# HR_C7000_DM32 register map
Vendor: Dahua Technology (chip); Baofeng (radio product); Series: HR_C7000; File version: 0.1-dm32re-draft
CPU: other r0p0, little endian, no MPU, no FPU, 0 interrupt priority bits
Registers are 32-bit, read-write, reset 0x0 unless marked. A register's access mark holds for its fields unless they carry their own. Offsets are from the block's base; [hi:lo] are bit positions.

## SDIO — SD/SDIO host, Synopsys DesignWare Mobile Storage (DS §5.5, p.285-325; FIFO depth 128, data FIFO window from +0x200). FW: no access found; QEMU: reports no card, as on the radio.
Base 0x15000000
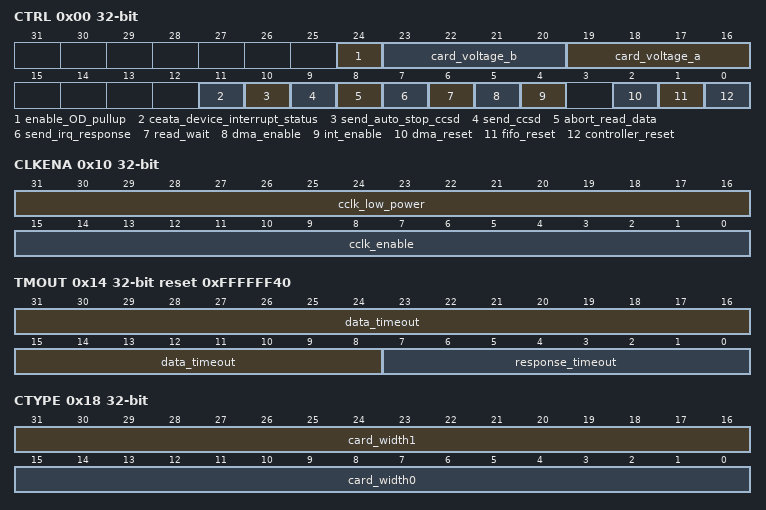
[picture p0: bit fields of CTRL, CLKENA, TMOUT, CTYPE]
0x00 CTRL — Control registers. DS §5.5.5.1 p.305. Note: H/S Represents hardware reset and software reset Reset 0x0 (DS).
  [24] enable_OD_pullup — External open-drain pull-up. 0: disabled; 1: enabled [reset 0x0] [access RW]
  [23:20] card_voltage_b — Card regulator B voltage setting, output to card_volt_b (optional; usable as a general output port) [reset 0x0] [access RW]
  [19:16] card_voltage_a — Card regulator A voltage setting, output to card_volt_a. Printed card_voltage_b (duplicate of [23:20]); DW_mobile_storage names this card_voltage_a [reset 0x0] [access RW]
  [11] ceata_device_interrupt_status — 0: CE-ATA device interrupts disabled; 1: enabled [reset 0x0] [access RW]
  [10] send_auto_stop_ccsd — Send internally generated STOP after sending CCSD to a CE-ATA device; send_ccsd must also be set [reset 0x0] [access RW]
  [9] send_ccsd — Send command-completion-signal-disable to a CE-ATA device [reset 0x0] [access RW]
  [8] abort_read_data — 1: reset the data state machine to IDLE; self-clearing [reset 0x0] [access RW]
  [7] send_irq_response — 1: send automatic IRQ response [reset 0x0] [access RW]
  [6] read_wait — 0: clear read wait; 1: assert read wait [reset 0x0] [access RW]
  [5] dma_enable — DMA transfer mode enable [reset 0x0] [access RW]
  [4] int_enable — Global interrupt enable [reset 0x0] [access RW]
  [2] dma_reset — Reset internal DMA interface logic; self-clears after two AHB clocks [reset 0x0] [access RW]
  [1] fifo_reset — Reset FIFO; self-clears when done [reset 0x0] [access RW]
  [0] controller_reset — Reset controller; self-clears after two AHB and two cclk_in cycles [reset 0x0] [access RW]
0x04 PWREN — Power-on enable register. DS §5.5.5.2 p.307. Reset 0x0 (DS).
  [0] power_enable — Card power: 1 = powered on, 0 = powered off. One bit per card; this design uses one controller per SD card and only bit 0 [reset 0x0] [access RW]
0x08 CLKDIV — Clock divider register. DS §5.5.5.3 p.307. Reset 0x0 (DS).
  [7:0] clk_divider0 — Divider 0: cclk_out = cclk_in / (2 * value); 0 = no division, 255 = divide by 510. Bits [31:8] (clk_divider1/2/3) not used, write 0 [reset 0x0] [access RW]
0x0C CLKSRC ro — Clock source register. DS §5.5.5.4 p.307. Reset 0x0 (DS).
  [31:0] clk_source — Select each SD The driving clock of the memory has the following relationship 00b : Select Clock divider_0 , 01 : Select Clock divider_1 , 10b : Select Clock divider_2 , 11 : Select Clock divider_3 , each controller in the project only contains clk_divder0 , which is fixed to 0 [reset 0x0] [access RO]
0x10 CLKENA — Clock enable register. DS §5.5.5.5 p.309. Reset 0x0 (DS).
  [31:16] cclk_low_power — 16 S D memory or 1 Zhang MMC Memory low power control 0 : Non-low power mode; 1 : Low power mode , the project only configures bit[16] , and all other bits are fixed to 0 [reset 0x0] [access RW]
  [15:0] cclk_enable — 16 S D memory or 1 Zhang MMC Memory clock enable control , 0 : Clock is invalid; 1 : Clock is enabled The project only configures bit[0] , and all other bits are fixed to 0 [reset 0x0] [access RW]
0x14 TMOUT reset 0xFFFFFF40 — Timeout register. DS §5.5.5.6 p.309. Reset 0xffffff40 (DS).
  [31:8] data_timeout — The memory card data reading timeout value is set, and the memory card clock starts counting after it ends. cclk_out of the selected card The period value is the unit time [reset 0xffffff] [access RW]
  [7:0] response_timeout — Reply timeout setting, with cclk_out The period value is the unit time [reset 0x40] [access RW]
0x18 CTYPE — Card Type Register. DS §5.5.5.7 p.309. Reset 0x0 (DS).
  [31:16] card_width1 — Indicates whether each memory card is 8-bit type 0 : non- 8-bit Type; 1 : 8-bit If there is no 8-bit application in the type project , write all 0s in this segment. [reset 0x0] [access RW]
  [15:0] card_width0 — Indicates whether each memory card is 1-bit or 4-bit type 0 : 1-bit Type ; 1 : 4-bit type The project only configures bit[0] and all other bits are written to 0 [reset 0x0] [access RW]
0x1C BLKSIZ reset 0x200 — Block size register. DS §5.5.5.8 p.310. Reset 0x200 (DS).
  [15:0] block_size — Block size (bytes ) [reset 0x200] [access RW]
0x20 BYTCNT reset 0x200 — Byte Count Register. DS §5.5.5.9 p.310. Reset 0x200 (DS).
  [31:0] byte_count — The number of bytes of data to be transferred For unknown data size transmission, 0 must be written [reset 0x200] [access RW]
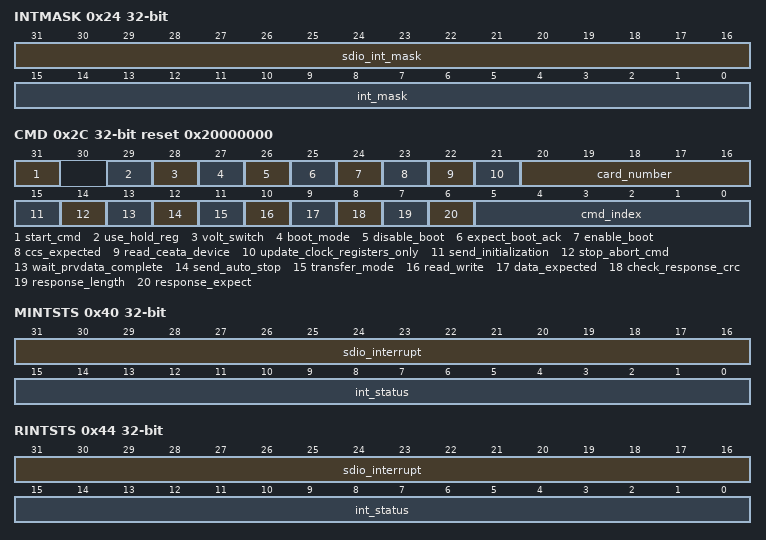
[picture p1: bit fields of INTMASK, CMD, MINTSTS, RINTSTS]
0x24 INTMASK — Interrupt Mask Register. DS §5.5.5.10 p.311. Reset 0x0 (DS).
  [31:16] sdio_int_mask — Shield 16 SDIO memory card Interrupt, 0 : mask; 1 : enable The project only configures bit[16] , and all other bits are written to 0 [reset 0x0] [access RW]
  [15:0] int_mask — Shield unwanted interrupts, 0 : Shield; 1 : Enable bit15 : End-bit error(read)/Write no CRC(EBE) bit14: Auto Command Done(ACD) bit13: Start Bit Error(SBE)/Busy Complete Iterrupt(BCI) bit12: Hardware Locked write Error(HLE) bit11: FIFO underrun/overrun Error(FRUN) bit10: Data starvation-by-host timeout(HTO)/Volt_switch_int bit9: Data Read Timeout(DRTO) bit8: Response Timeout(RTO) bit7: Data CRC Error(DCRC) bit6: Responese CRC Error (RCRC) bit5: Receive FIFO Data Request(RXDR) bit4: Transmit FIFO Data Request(TXDR) bit3: Data Transfer Over(DTO) bit2: Command done(CD) bit1: Response Error(RE) bit0: Card Detect(CD) [reset 0x0] [access RW]
0x28 CMDARG — Instruction content segment register. DS §5.5.5.11 p.311. Reset 0x0 (DS).
  [31:0] cmd_arg — 32bit transmitted to the card Instruction content [reset 0x0] [access RW]
0x2C CMD reset 0x20000000 — Command register. DS §5.5.5.12 p.311. Reset 0x20000000 (DS).
  [31] start_cmd — Send instructions, CIU After receiving the instruction, this bit is automatically cleared [reset 0x0] [access RW]
  [29] use_hold_reg — 0 : CMD and DATA Not through HOLD Registers sent to memory card 1 : CMD and DATA through HOLD Register sent to memory card [reset 0x1] [access RW]
  [28] volt_switch — 0 : No voltage switching 1 : Voltage switching enabled, send CMD11 Must be set when [reset 0x0] [access RW]
  [27] boot_mode — Boot Mode selection: 0 : Must boot operate 1 : Optional boot operate [reset 0x0] [access RW]
  [26] disable_boot — Boot invalid [reset 0x0] [access RW]
  [25] expect_boot_ack — ( CIU ) hopes to obtain boot Response [reset 0x0] [access RW]
  [24] enable_boot — Enable boot [reset 0x0] [access RW]
  [23] ccs_expected — 0 : CE_ATA The interrupt in the device is invalid, or the command does not need to get the device CCS (Command Complete Signal .) 1 : CE_ATA Device internal interrupt enable, RW_BLK Need from CE_ATA The device's CCS (Command Completion Signal .) If there is no CE-ATA application, this bit is written as 0. [reset 0x0] [access RW]
  [22] read_ceata_device — 0 : The host does not send data to CE_ATA. Device reads data 1 : Master end to CE-ATA If the device reads data without CE- ATA application, this bit is written as 0. [reset 0x0] [access RW]
  [21] update_clock_registers_only — 0 : Normal instruction sequence 1 : Do not send instructions, only update the clock register [reset 0x0] [access RW]
  [20:16] card_number — Current valid card number [reset 0x0] [access RW]
  [15] send_initialization — 0 : Do not send the initialization sequence before sending the command 1 : Send initialization sequence before sending command 80 must be executed before sending any command to the card. c l o c k s Initialize the card. [reset 0x0] [access RW]
  [14] stop_abort_cmd — 0 : Do not stop or abandon the current data transfer 1 : Stop or abandon the current data transmission [reset 0x0] [access RW]
  [13] wait_prvdata_complete — 0 : Send new command regardless of whether the previous data transmission is completed 1 : Wait for the last data transmission to complete before sending a new command [reset 0x0] [access RW]
  [12] send_auto_stop — 0 : After data transmission is completed, no (automatic) stop command is issued 1 : After data transmission is completed, a (automatic) stop command is issued [reset 0x0] [access RW]
  [11] transfer_mode — 0 : Data block transmission instruction; 1 : Data stream transmission instruction [reset 0x0] [access RW]
  [10] read_write — 0 : read; 1 : write [reset 0x0] [access RW]
  [9] data_expected — 0 : No data reading or writing; 1 : Data reading or writing [reset 0x0] [access RW]
  [8] check_response_crc — 0 : No CRC response Check; 1 : Perform reply CRC check [reset 0x0] [access RW]
  [7] response_length — 0 : short reply; 1 : long reply [reset 0x0] [access RW]
  [6] response_expect — 0 : No reply; 1 : Reply [reset 0x0] [access RW]
  [5:0] cmd_index — Instruction number [reset 0x0] [access RW]
0x30 RESP0 ro — Response reply register 0. DS §5.5.5.13 p.314. Reset 0x0 (DS).
  [31:0] response0 — Reply register 0 , short response or long response bit [31:0] [reset 0x0] [access RO]
0x34 RESP1 ro — Response reply register 1. DS §5.5.5.14 p.315. Reset 0x0 (DS).
  [31:0] response1 — Reply register 1 , long response bits [63:32] auto_Stop response is stored in this register [reset 0x0] [access RO]
0x38 RESP2 ro — Response reply register 2. DS §5.5.5.15 p.315. Reset 0x0 (DS).
  [31:0] response2 — Reply register 2 , long response bit [95:64] [reset 0x0] [access RO]
0x3C RESP3 ro — Response reply register 3. DS §5.5.5.16 p.315. Reset 0x0 (DS).
  [31:0] response3 — Reply register 3 , long response bit [127:96] [reset 0x0] [access RO]
0x40 MINTSTS ro — Interrupt Mask Register. DS §5.5.5.17 p.315. Note: MISTATUS = RINTSTS and INTMASK Reset 0x0 (DS).
  [31:16] sdio_interrupt — Unshielded memory card SDIO Interrupt status, each bit For a card: Bit[31] corresponds to card[15], bit[16] c o r r e s p o nd s t o card[0] . 0 : No SDIO interrupt is sent from the memory card 1 : With SDIO Interrupt sent from memory card The project only uses bit[16] [reset 0x0] [access RO]
  [15:0] int_status — Masked interrupt status (MINTSTS = RINTSTS & INTMASK); same bit assignment as RINTSTS.int_status [reset 0x0] [access RO]
0x44 RINTSTS — Interrupt Status Register. DS §5.5.5.18 p.317. Reset 0x0 (DS).
  [31:16] sdio_interrupt write-1-clears — SDIO interrupt per card, regardless of mask: bit 16 = card 0 ... bit 31 = card 15. Only bit 16 is used in this design. Write 1 to clear [reset 0x0] [access RO/WC]
  [15:0] int_status write-1-clears — Raw interrupt status, write 1 to clear: 15 EBE end-bit error/write no CRC; 14 ACD auto command done; 13 SBE start-bit error/BCI busy complete; 12 HLE hardware locked write error; 11 FRUN FIFO under/overrun; 10 HTO data starvation timeout/volt_switch_int; 9 DRTO data read timeout; 8 RTO response timeout; 7 DCRC data CRC error; 6 RCRC response CRC error; 5 RXDR RX FIFO data request; 4 TXDR TX FIFO data request; 3 DTO data transfer over; 2 CD command done; 1 RE response error; 0 CD card detect [reset 0x0] [access RO/WC]
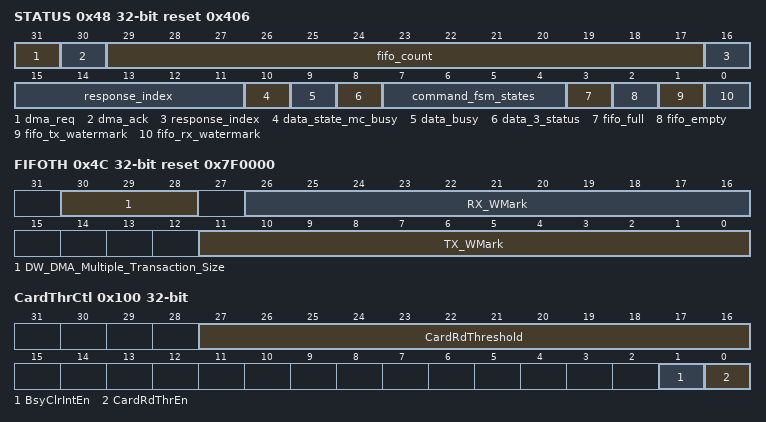
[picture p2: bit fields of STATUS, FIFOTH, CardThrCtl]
0x48 STATUS ro reset 0x406 — Status register, mainly used to check the. DS §5.5.5.19 p.318. Reset 0x406 (DS).
  [31] dma_req — DMA Request signal status bit [reset 0x0] [access RO]
  [30] dma_ack — DMA Response signal status bit [reset 0x0] [access RO]
  [29:17] fifo_count — The amount of data written into the FIFO [reset 0x0] [access RO]
  [16:11] response_index — Previous reply index number [reset 0x0] [access RO]
  [10] data_state_mc_busy — Data sending or receiving state machine is busy [reset 0x1] [access RO]
  [9] data_busy — The opposite value of card_data [0] 0 : Memory card data is not busy; 1 : Memory card data is busy [reset 0x0] [access RO]
  [8] data_3_status — Select the storage card card_datap[3] signal to detect whether there is a card. 0 : Memory card present; 1 : No memory card present [reset 0x0] [access RO]
  [7:4] command_fsm_states — Indicates the current state of the command state machine: 0- IDLE 1- Send init sequence 2- Tx cmd start bit 3- Tx cmd bit 4- Tx cmd index + arg 5- Tx cmd crc7 6- Tx cmd end bit 7- Rx resp start bit 8- Rx resp IRQ response 9- Rx resp tx bit 10- Rx resp cmd idx 11- Rx resp data 12- Rx resp crc7 13- Rx resp end bit 14- Cmd path wait NCC 15- Wait , CMD_to_response turnaround [reset 0x0] [access RO]
  [3] fifo_full — FIFO full flag [reset 0x0] [access RO]
  [2] fifo_empty — FIFO empty flag [reset 0x1] [access RO]
  [1] fifo_tx_watermark — FIFO reaches the send watermark value [reset 0x1] [access RO]
  [0] fifo_rx_watermark — FIFO reaches the receive waterline value [reset 0x0] [access RO]
0x4C FIFOTH reset 0x7F0000 — FIFO Threshold Register. DS §5.5.5.20 p.319. Bit 27 is not listed in the datasheet (reserved). Reset 0x7f0000 (DS).
  [30:28] DW_DMA_Multiple_Transaction_Size — DMA burst size, must match DW_DMA SRC/DEST_MSIZE. 000: 1; 001: 4; 010: 8; 011: 16; 100: 32; 101: 64; 110: 128; 111: 256 transfers (1 transfer = H_DATA_WIDTH) [reset 0x0] [access RW]
  [26:16] RX_WMark — RX watermark: request when FIFO data exceeds this (FIFO_DEPTH is 128 in this design) [reset 0x7f] [access RW]
  [11:0] TX_WMark — TX watermark: request when FIFO data falls below this [reset 0x0] [access RW]
0x50 CDETECT ro — Card detection register. DS §5.5.5.21 p.321.
  [29:0] card_detect_n — Input port card_detect_n The value on the card ( 1 bit for each card ), 0 : card detected; 1 : card not detected The project only uses bit[0] [reset card_detect_n_inputs] [access RO]
0x54 WRTPRT ro — Write protection register. DS §5.5.5.22 p.321.
  [29:0] write_protect — Value on the card_write_prt input port, one bit per card. 0: not write-protected; 1: write-protected. Only bit 0 is used in this design [reset card_write_prt_inputs] [access RO]
0x5C TCBCNT ro — CIU Byte transmitted by the module Number. DS §5.5.5.23 p.321. Reset 0x0 (DS).
  [31:0] trans_card_byte_count — By module CIU The number of data bytes sent to the Card [reset 0x0] [access RO]
0x60 TBBCNT ro — Host with BIU_FIFO byte of interaction data. DS §5.5.5.24 p.321. Reset 0x0 (DS).
  [31:0] trans_fifo_byte_count — Host with BIU-FIFO The number of bytes of data transferred between [reset 0x0] [access RO]
0x64 DEBNCE reset 0xFFFFFF — Card detection bounce register ( unit is. DS §5.5.5.25 p.322. Reset 0xffffff (DS).
  [23:0] debounce_count — The value of the debounce filter logic is in the unit of the master clock cycle. The typical value is 5-25ms [reset 0xffffff] [access RW]
0x68 USRID reset 0x45700311 — User ID Register. DS §5.5.5.26 p.323. Reset 0x45700311 (DS).
  [31:0] usrid — User ID register, set by the user. [reset 0x45700311] [access RW]
0x6C VERID ro reset 0x5342250A — Soft core version ID register. DS §5.5.5.27 p.323. Reset 0x5342250a (DS).
  [31:0] Verid — Synopsys Soft core version number register [reset 0x5342250a] [access RO]
0x70 HCON ro reset 0xC44CC1 — Hardware Configuration Registers. DS §5.5.5.28 p.323. Reset 0xc44cc1 (DS).
  [31:0] hcon — User-generated IP Before, configure this register to associate with the hardware configuration Software Development [reset 0x00c44cc1] [access RO]
0x78 RST_n reset 0x1 — Hard reset register. DS §5.5.5.29 p.323. Reset 0x1 (DS).
  [15:0] card_reset — MMC Card reset control ( generated on the top-level port rst_n Signal ) 0 : Reset; 1 : Activate The project only uses bit[0] [reset 0x1] [access RW]
0x100 CardThrCtl — Card read threshold enable register. DS §5.5.5.30 p.323. Reset 0x0 (DS).
  [27:16] CardRdThreshold — Card read threshold size. Printed [N:16] with N set by FIFO size; FIFO_DEPTH is 128 so N=27 [reset 0x0] [access RW]
  [1] BsyClrIntEn — Busy-clear interrupt enable [reset 0x0] [access RW]
  [0] CardRdThrEn — Card read threshold enable [reset 0x0] [access RW]
0x104 Back_end_power — Back_end Power register. DS §5.5.5.31 p.325. Reset 0x0 (DS).
  [15:0] back_end_power — back_end power supply, 0 : power off; 1 : power on, one pin per card [reset 0x0] [access RW]
0x110 ENABLE_SHIFT — Conversion Phase Control Register. DS §5.5.5.32 p.325. Reset 0x0 (DS).
  [31:0] Enable_shift — The default phase shift value in the control design is controlled by 1 for every 2 bits . memory cards 00 : Default phase shift; 01 : Enable phase shift on the next clock rising edge 10 : Enable phase shift at the next clock falling edge; 11 : Reserved [reset 0x0] [access RW]
0x200 DATA — DS §5.5.5.33 p.325. Reset 0x0 (DS).
  [31:0] FIFO — Data read and write FIFO entry address, Random reading and writing of FIFO may cause logic disorder [reset 0x0] [access RW]
